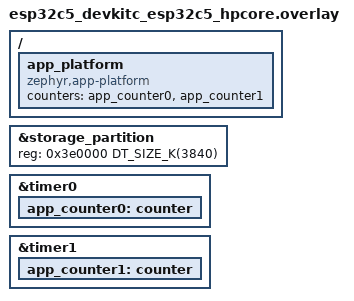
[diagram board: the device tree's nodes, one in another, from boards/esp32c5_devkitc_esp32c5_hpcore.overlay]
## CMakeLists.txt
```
# SPDX-License-Identifier: Apache-2.0

cmake_minimum_required(VERSION 3.20.0)
find_package(Zephyr REQUIRED HINTS $ENV{ZEPHYR_BASE})
project(app_platform_test)

target_sources(app PRIVATE src/main.c src/loader_neg.c src/abi.c src/caps.c src/keys.c
  src/module_run.c)
target_sources_ifdef(CONFIG_USERSPACE app PRIVATE src/hostile.c)
if(CONFIG_APP_PLATFORM_APP_THREADS GREATER 0)
  target_sources(app PRIVATE src/threads.c)
endif()
if(CONFIG_APP_PLATFORM_APP_HEAP_POOL_SIZE GREATER 0)
  target_sources(app PRIVATE src/heap.c)
endif()
target_sources_ifdef(CONFIG_APP_PLATFORM_CPU_AFFINITY app PRIVATE src/smp.c)

set(gen_dir ${ZEPHYR_BINARY_DIR}/include/generated)
set(key_dir ${CMAKE_CURRENT_SOURCE_DIR}/keys)
set(ext_src ${PROJECT_SOURCE_DIR}/module/src/test_mod.c)
set(bin ${PROJECT_BINARY_DIR}/llext/test_mod.llext)

app_platform_add_module(test_ext OUTPUT ${bin} SOURCES ${ext_src})
llext_include_directories(test_ext ${gen_dir})
generate_inc_file_for_target(app ${bin} ${gen_dir}/test_mod.inc)

# A module calling a service the firmware is built without.
set(absent_bin ${PROJECT_BINARY_DIR}/llext/absent_mod.llext)
app_platform_add_module(absent_ext OUTPUT ${absent_bin}
  SOURCES ${PROJECT_SOURCE_DIR}/module/src/absent_mod.c)
generate_inc_file_for_target(app ${absent_bin} ${gen_dir}/absent_mod.inc)

# A module importing a function outside the exported interface.
set(forbidden_bin ${PROJECT_BINARY_DIR}/llext/forbidden_mod.llext)
app_platform_add_module(forbidden_ext OUTPUT ${forbidden_bin}
  SOURCES ${PROJECT_SOURCE_DIR}/module/src/forbidden_mod.c)
generate_inc_file_for_target(app ${forbidden_bin} ${gen_dir}/forbidden_mod.inc)

# test_sign(<tag> <module> <name> [-D<input>=<value>...])
#
# Signs <module> as application <name>, version 1, requesting LOG, with the
# test publisher key 1 of test_keys.yaml, into <tag>.manifest.inc and
# <tag>.sig.inc. The extra arguments override those inputs of
# sign_module.cmake: an empty APP_SIGNING_KEY signs with the key under KEY_DIR,
# by default the development key.
function(test_sign tag module name)
  set(out_mf  ${gen_dir}/${tag}.manifest.inc)
  set(out_sig ${gen_dir}/${tag}.sig.inc)
  string(MAKE_C_IDENTIFIER ${tag} target)

  add_custom_command(
    OUTPUT  ${out_mf} ${out_sig}
    COMMAND ${CMAKE_COMMAND}
      -DMODULE_BIN=${module}
      -DKEY_DIR=${key_dir}
      -DAPP_SIGNING_KEY=${key_dir}/publisher_a.pem
      -DAPP_SIGNING_KEY_ID=1
      -DAPP_NAME=${name}
      -DAPP_VERSION=1
      -DAPP_REQUESTED_CAPS=LOG
      -DABI_FILE=${APP_PLATFORM_ABI_FILE}
      ${ARGN}
      -DOUT_MF_INC=${out_mf}
      -DOUT_SIG_INC=${out_sig}
      -DPYTHON_EXECUTABLE=${PYTHON_EXECUTABLE}
      -P ${ZEPHYR_BASE}/subsys/app_platform/cmake/sign_module.cmake
    DEPENDS ${module} ${APP_PLATFORM_ABI_FILE}
  )
  add_custom_target(${target}_sign DEPENDS ${out_mf} ${out_sig})
  add_dependencies(${target}_sign app_platform_abi)
  add_dependencies(app ${target}_sign)
endfunction()

test_sign(test_mod ${bin} testmod)

# The same module signed for another interface major version, under a manifest
# carrying fields past the ones the firmware knows, under one cut short of
# them, signed for another target, with a heap, and requesting and requiring
# more capabilities.
test_sign(test_mod.badabi ${bin} testmod -DABI_MAJOR_OVERRIDE=0xffff)
test_sign(test_mod.long ${bin} testmod -DMANIFEST_LEN=200)
test_sign(test_mod.short ${bin} testmod -DMANIFEST_LEN=100)
test_sign(test_mod.target ${bin} testmod -DTARGET_OVERRIDE=0)
test_sign(test_mod.heap ${bin} testmod -DAPP_HEAP_SIZE=992)
test_sign(test_mod.caps ${bin} testmod -DAPP_REQUESTED_CAPS=LOG,TIME,RANDOM
  -DAPP_REQUIRED_CAPS=LOG,TIME)

# The module importing a forbidden function, signed without the signer's import
# check for the loader's.
test_sign(forbidden_mod ${forbidden_bin} forbidden -DSKIP_IMPORT_CHECK=1)

# The same module signed with the development key, with a key test_keys.yaml
# does not list, with a revoked key, and with publisher key 2, whose ceiling is
# LOG and whose names start with b_: within its limits, requiring a capability
# outside its ceiling and under a name outside its prefix. The signer refuses
# all but one of them, so its key check is skipped.
test_sign(test_mod.dev ${bin} testmod -DAPP_SIGNING_KEY= -DAPP_SIGNING_KEY_ID=0
  -DSKIP_KEY_CHECK=1)
test_sign(test_mod.unknown ${bin} testmod -DKEY_DIR=${PROJECT_BINARY_DIR}/unlisted_key
  -DAPP_SIGNING_KEY= -DAPP_SIGNING_KEY_ID=7 -DSKIP_KEY_CHECK=1)
test_sign(test_mod.revoked ${bin} testmod -DAPP_SIGNING_KEY=${key_dir}/revoked.pem
  -DAPP_SIGNING_KEY_ID=3 -DSKIP_KEY_CHECK=1)
test_sign(test_mod.b ${bin} b_mod -DAPP_SIGNING_KEY=${key_dir}/publisher_b.pem
  -DAPP_SIGNING_KEY_ID=2 -DAPP_REQUESTED_CAPS=LOG,TIME,RANDOM -DAPP_REQUIRED_CAPS=LOG)
test_sign(test_mod.breq ${bin} b_req -DAPP_SIGNING_KEY=${key_dir}/publisher_b.pem
  -DAPP_SIGNING_KEY_ID=2 -DAPP_REQUESTED_CAPS=LOG,TIME -DAPP_REQUIRED_CAPS=LOG,TIME
  -DSKIP_KEY_CHECK=1)
test_sign(test_mod.bname ${bin} testmod -DAPP_SIGNING_KEY=${key_dir}/publisher_b.pem
  -DAPP_SIGNING_KEY_ID=2 -DSKIP_KEY_CHECK=1)

# A signed-but-malformed module (out-of-section relocation) for the loader's
# relocation bounds-check test.
set(evil    ${gen_dir}/evil_mod.inc)
set(evil_mf ${gen_dir}/evil_mod.manifest.inc)
set(evil_sig ${gen_dir}/evil_mod.sig.inc)

add_custom_command(
  OUTPUT  ${evil} ${evil_mf} ${evil_sig}
  COMMAND ${CMAKE_COMMAND}
    -DMODULE_BIN=${bin}
    -DAPP_SIGNING_KEY=${key_dir}/publisher_a.pem
    -DAPP_SIGNING_KEY_ID=1
    -DAPP_NAME=evil
    -DAPP_VERSION=1
    -DAPP_REQUESTED_CAPS=LOG
    -DABI_FILE=${APP_PLATFORM_ABI_FILE}
    -DOUT_INC=${evil}
    -DOUT_MF_INC=${evil_mf}
    -DOUT_SIG_INC=${evil_sig}
    -DPYTHON_EXECUTABLE=${PYTHON_EXECUTABLE}
    -DZEPHYR_BASE=${ZEPHYR_BASE}
    -P ${CMAKE_CURRENT_SOURCE_DIR}/cmake/make_evil.cmake
  DEPENDS ${bin} ${APP_PLATFORM_ABI_FILE}
)
add_custom_target(test_evil DEPENDS ${evil} ${evil_mf} ${evil_sig})
add_dependencies(test_evil app_platform_abi)
add_dependencies(app test_evil)
```

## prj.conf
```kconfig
CONFIG_ZTEST=y

CONFIG_APPLICATION_DEFINED_SYSCALL=y

CONFIG_APP_PLATFORM=y
CONFIG_APP_PLATFORM_MAX_APPS=4
CONFIG_APP_PLATFORM_APP_THREADS=2
CONFIG_APP_PLATFORM_APP_HEAP_POOL_SIZE=12288
CONFIG_APP_PLATFORM_APP_HEAP_MAX_BYTES=65536
CONFIG_APP_PLATFORM_LOADER=y
CONFIG_APP_PLATFORM_DEV_KEY=y
CONFIG_APP_PLATFORM_KEYS_FILE="test_keys.yaml"
CONFIG_APP_PLATFORM_SERVICES=y
CONFIG_APP_PLATFORM_REGISTRY=y

CONFIG_TASK_WDT=y
CONFIG_TASK_WDT_CHANNELS=6
CONFIG_TASK_WDT_HW_FALLBACK=n

CONFIG_LLEXT=y
CONFIG_LLEXT_HEAP_SIZE=64
CONFIG_LLEXT_TYPE_ELF_RELOCATABLE=y

CONFIG_FLASH=y
CONFIG_FLASH_MAP=y
CONFIG_FILE_SYSTEM=y
CONFIG_FILE_SYSTEM_LITTLEFS=y

CONFIG_PSA_CRYPTO=y
CONFIG_MBEDTLS_ENABLE_HEAP=y
CONFIG_PSA_WANT_ALG_SHA_256=y
CONFIG_PSA_WANT_ALG_ECDSA=y
CONFIG_PSA_WANT_ECC_SECP_R1_256=y
CONFIG_PSA_WANT_KEY_TYPE_ECC_PUBLIC_KEY=y
CONFIG_MBEDTLS_PSA_P256M_DRIVER_ENABLED=y

CONFIG_ENTROPY_GENERATOR=y

CONFIG_LOG=y
CONFIG_LOG_MODE_MINIMAL=y

CONFIG_MAIN_STACK_SIZE=4096
CONFIG_ZTEST_STACK_SIZE=4096
CONFIG_HEAP_MEM_POOL_SIZE=32768

CONFIG_SENSOR=y
CONFIG_APP_PLATFORM_SENSOR=y
CONFIG_APP_PLATFORM_FS=y
CONFIG_GPIO=y
CONFIG_APP_PLATFORM_IO=y
CONFIG_APP_PLATFORM_EVENTS=y
CONFIG_FS_LITTLEFS_NUM_FILES=8
CONFIG_COUNTER=y
CONFIG_APP_PLATFORM_COUNTER=y
```

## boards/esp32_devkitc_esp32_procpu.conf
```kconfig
# The llext instruction heap lives in IRAM here, and its k_heap needs the
# big-only sys_heap variant or heap init faults before the console is up.
CONFIG_SYS_HEAP_BIG_ONLY=y
```

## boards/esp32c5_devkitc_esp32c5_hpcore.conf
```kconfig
# Internal RAM is short in the user mode build, which reserves a privileged
# stack for every application thread.
CONFIG_APP_PLATFORM_APP_HEAP_POOL_SIZE=3072
```

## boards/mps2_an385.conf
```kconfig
# Without an entropy driver mbed TLS runs its own DRBG from its heap.
CONFIG_MBEDTLS_HEAP_SIZE=4096
```

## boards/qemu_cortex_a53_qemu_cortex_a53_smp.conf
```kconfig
# Without an entropy driver mbed TLS runs its own DRBG from its heap.
CONFIG_MBEDTLS_HEAP_SIZE=4096
CONFIG_APP_PLATFORM_CPU_AFFINITY=y
# The CPU affinity suite counts thread switch-ins per CPU.
CONFIG_TRACING=y
CONFIG_TRACING_USER=y
```

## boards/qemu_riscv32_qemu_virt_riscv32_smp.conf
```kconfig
# Without an entropy driver mbed TLS runs its own DRBG from its heap.
CONFIG_MBEDTLS_HEAP_SIZE=4096
# Ticks match milliseconds, so the test module needs no 64-bit division helper.
CONFIG_SYS_CLOCK_TICKS_PER_SEC=1000
CONFIG_APP_PLATFORM_CPU_AFFINITY=y
# The CPU affinity suite counts thread switch-ins per CPU.
CONFIG_TRACING=y
CONFIG_TRACING_USER=y
```

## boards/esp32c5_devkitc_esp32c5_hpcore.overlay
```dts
/*
 * Copyright (c) 2026 Espressif Systems (Shanghai) Co., Ltd.
 *
 * SPDX-License-Identifier: Apache-2.0
 *
 * Enlarge the storage partition for the application store. Under simple boot
 * the second firmware slot is unused, so its region is reassigned to storage,
 * growing the littlefs area from 192 KB to 3.8 MB for many or larger apps. The
 * code partition and the low-power-core slots are left untouched.
 */

/delete-node/ &slot1_partition;

&storage_partition {
	reg = <0x3e0000 DT_SIZE_K(3840)>;
};

/* Two counter instances for the hardware counter service: the suite grants one
 * and withholds the other, so the per-instance grant is testable.
 */
&timer0 {
	status = "okay";

	app_counter0: counter {
		status = "okay";
	};
};

&timer1 {
	status = "okay";

	app_counter1: counter {
		status = "okay";
	};
};

/ {
	app_platform {
		compatible = "zephyr,app-platform";
		counters = <&app_counter0 &app_counter1>;
	};
};
```

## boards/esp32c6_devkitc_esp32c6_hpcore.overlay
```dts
/*
 * Copyright (c) 2026 Espressif Systems (Shanghai) Co., Ltd.
 *
 * SPDX-License-Identifier: Apache-2.0
 *
 * Enlarge the storage partition for the application store. Under simple boot
 * the second firmware slot is unused, so its region is reassigned to storage.
 * The code partition and the low-power-core slots are left untouched.
 */

/delete-node/ &slot1_partition;

&storage_partition {
	reg = <0x1e0000 DT_SIZE_K(1792)>;
};

/* Two counter instances for the hardware counter service: the suite grants one
 * and withholds the other, so the per-instance grant is testable.
 */
&timer0 {
	status = "okay";

	app_counter0: counter {
		status = "okay";
	};
};

&timer1 {
	status = "okay";

	app_counter1: counter {
		status = "okay";
	};
};

/ {
	app_platform {
		compatible = "zephyr,app-platform";
		counters = <&app_counter0 &app_counter1>;
	};
};
```

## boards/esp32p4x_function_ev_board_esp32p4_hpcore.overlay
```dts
/*
 * Copyright (c) 2026 Espressif Systems (Shanghai) Co., Ltd.
 *
 * SPDX-License-Identifier: Apache-2.0
 *
 * Enlarge the storage partition for the application store. Under simple boot
 * the second firmware slot is unused, so its region is reassigned to storage,
 * growing the littlefs area from 192 KB to 3.8 MB for many or larger apps. The
 * code partition and the low-power-core slots are left untouched.
 */

/delete-node/ &slot1_partition;

&storage_partition {
	reg = <0x7e0000 DT_SIZE_K(3840)>;
};

/* Two counter instances for the hardware counter service: the suite grants one
 * and withholds the other, so the per-instance grant is testable.
 */
&timer0 {
	status = "okay";

	app_counter0: counter {
		status = "okay";
	};
};

&timer1 {
	status = "okay";

	app_counter1: counter {
		status = "okay";
	};
};

/ {
	app_platform {
		compatible = "zephyr,app-platform";
		counters = <&app_counter0 &app_counter1>;
	};
};
```

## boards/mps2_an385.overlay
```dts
/*
 * Copyright (c) 2026 Espressif Systems (Shanghai) Co., Ltd.
 *
 * SPDX-License-Identifier: Apache-2.0
 */

/ {
	app_platform {
		compatible = "zephyr,app-platform";
		counters = <&timer0 &timer1>;
	};
};
```

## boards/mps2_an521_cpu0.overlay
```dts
/*
 * Copyright (c) 2026 Espressif Systems (Shanghai) Co., Ltd.
 *
 * SPDX-License-Identifier: Apache-2.0
 */

#include <mem.h>
#include "sim_flash.dtsi"

/ {
	app_platform {
		compatible = "zephyr,app-platform";
		counters = <&timer0 &timer1>;
	};
};
```

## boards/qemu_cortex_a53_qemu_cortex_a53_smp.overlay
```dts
/*
 * Copyright (c) 2026 Espressif Systems (Shanghai) Co., Ltd.
 *
 * SPDX-License-Identifier: Apache-2.0
 */

#include <mem.h>
#include "sim_flash.dtsi"
```

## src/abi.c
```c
/*
 * Copyright (c) 2026 Espressif Systems (Shanghai) Co., Ltd.
 *
 * SPDX-License-Identifier: Apache-2.0
 */

/* The functions the firmware exports to loadable modules. */

#include <zephyr/ztest.h>
#include <zephyr/app_platform/app_loader.h>
#include <zephyr/app_platform/app_manifest.h>
#include <zephyr/app_platform/app_platform.h>
#include <zephyr/llext/buf_loader.h>
#include <zephyr/llext/llext.h>
#include <zephyr/kernel.h>
#include <errno.h>
#include <string.h>

#include "module_run.h"

/* Argument that makes the test module check the kernel services and return. */
#define TIME_PROBE ((void *)0x5449U)

/* Argument that makes the test module check 64-bit division and return. */
#define DIV_PROBE ((void *)0x4449U)

static const uint8_t mod_bytes[] = {
#include "test_mod.inc"
};
static const uint8_t mod_manifest[] = {
#include "test_mod.manifest.inc"
};
static const uint8_t mod_sig[] = {
#include "test_mod.sig.inc"
};
static const uint8_t absent_bytes[] __aligned(8) = {
#include "absent_mod.inc"
};

ZTEST(module_abi, test_kernel_services)
{
	struct app_manifest mf;
	struct llext *ext = NULL;
	void *entry = NULL;
	int id;

	zassert_true(sizeof(mod_bytes) <= sizeof(module_work), "module too big");
	memcpy(module_work, mod_bytes, sizeof(mod_bytes));
	memcpy(&mf, mod_manifest, sizeof(mf));
	zassert_equal(app_loader_verify_load_manifest(&mf, sizeof(mf), mod_sig, sizeof(mod_sig),
						      module_work, sizeof(mod_bytes), "app_main",
						      &ext, &entry),
		      0);

	module_watch(mf.name);
	id = app_platform_launch_llext(mf.name, ext, (app_entry_t)entry, TIME_PROBE,
				       APP_CAP_LOG);
	zassert_true(id >= 0, "launch rc %d", id);
	zassert_equal(module_wait_end(id, 3000), 0, "the module did not return");
}

ZTEST(module_abi, test_64bit_division)
{
	struct app_manifest mf;
	struct llext *ext = NULL;
	void *entry = NULL;
	int id;

	memcpy(module_work, mod_bytes, sizeof(mod_bytes));
	memcpy(&mf, mod_manifest, sizeof(mf));
	zassert_equal(app_loader_verify_load_manifest(&mf, sizeof(mf), mod_sig, sizeof(mod_sig),
						      module_work, sizeof(mod_bytes), "app_main",
						      &ext, &entry),
		      0);

	module_watch(mf.name);
	id = app_platform_launch_llext(mf.name, ext, (app_entry_t)entry, DIV_PROBE, APP_CAP_LOG);
	zassert_true(id >= 0, "launch rc %d", id);
	zassert_equal(module_wait_end(id, 3000), 0, "the module did not return");
}

ZTEST(module_abi, test_missing_service_fails_to_link)
{
	struct llext_buf_loader buf_loader =
		LLEXT_TEMPORARY_BUF_LOADER(absent_bytes, sizeof(absent_bytes));
	struct llext_load_param ldr_parm = LLEXT_LOAD_PARAM_DEFAULT;
	struct llext *ext = NULL;
	int ret;

	/* A missing symbol reached through the PLT reports -ENOENT. */
	ret = llext_load(&buf_loader.loader, "absent", &ext, &ldr_parm);
	zassert_true(ret == -ENODATA || ret == -ENOENT, "load rc %d", ret);
	zassert_is_null(ext);
}

ZTEST_SUITE(module_abi, NULL, NULL, NULL, NULL, NULL);
```

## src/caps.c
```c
/*
 * Copyright (c) 2026 Espressif Systems (Shanghai) Co., Ltd.
 *
 * SPDX-License-Identifier: Apache-2.0
 */

/* The capabilities a loaded module holds: what its signed manifest requests,
 * bounded by the launcher, or what the launcher allows without a manifest.
 */

#include <zephyr/ztest.h>
#include <zephyr/app_platform/app_caps.h>
#include <zephyr/app_platform/app_loader.h>
#include <zephyr/app_platform/app_manifest.h>
#include <zephyr/app_platform/app_platform.h>
#include <zephyr/app_platform/app_registry.h>
#include <zephyr/llext/llext.h>
#include <zephyr/kernel.h>
#include <errno.h>
#include <string.h>

#include "module_run.h"

static const uint8_t mod_bytes[] = {
#include "test_mod.inc"
};
static const uint8_t caps_manifest[] = {
#include "test_mod.caps.manifest.inc"
};
static const uint8_t caps_sig[] = {
#include "test_mod.caps.sig.inc"
};

#define REQUESTED (APP_CAP_LOG | APP_CAP_TIME | APP_CAP_RANDOM)

static struct llext *load_caps_module(struct app_manifest *mf, void **entry)
{
	struct llext *ext = NULL;

	zassert_true(sizeof(mod_bytes) <= sizeof(module_work), "module too big");
	memcpy(module_work, mod_bytes, sizeof(mod_bytes));
	memcpy(mf, caps_manifest, sizeof(*mf));
	zassert_equal(app_loader_verify_load_manifest(mf, sizeof(*mf), caps_sig, sizeof(caps_sig),
						      module_work, sizeof(mod_bytes), "app_main",
						      &ext, entry),
		      0);
	return ext;
}

static void unload(struct llext *ext)
{
	app_loader_forget(ext);
	llext_unload(&ext);
}

/* Launch stopped, read the capabilities the application holds, remove it. */
static int held_caps(const char *name, struct llext *ext, void *entry, app_caps_t ceiling,
		     app_caps_t *caps)
{
	const struct app_launch_opts opts = {.stopped = true};
	struct app_platform_status st;
	int id = app_platform_launch_llext_opts(name, ext, (app_entry_t)entry, NULL, ceiling,
						&opts);

	if (id < 0) {
		return id;
	}
	zassert_equal(app_platform_status(id, &st), 0);
	*caps = st.caps;
	zassert_equal(app_platform_remove(id), 0);
	for (int i = 0; i < 400 && app_platform_status(id, &st) == 0; i++) {
		k_msleep(5);
	}
	return 0;
}

ZTEST(module_caps, test_manifest_request_bounds_the_ceiling)
{
	struct app_manifest mf;
	app_caps_t caps = 0U;
	void *entry = NULL;
	struct llext *ext = load_caps_module(&mf, &entry);

	zassert_equal(mf.requested_caps, REQUESTED);
	zassert_equal(held_caps(mf.name, ext, entry, APP_CAP_ALL, &caps), 0);
	zassert_equal(caps, REQUESTED, "held %#llx", (unsigned long long)caps);
}

ZTEST(module_caps, test_optional_caps_outside_ceiling_dropped)
{
	struct app_manifest mf;
	app_caps_t caps = 0U;
	void *entry = NULL;
	struct llext *ext = load_caps_module(&mf, &entry);

	zassert_equal(held_caps(mf.name, ext, entry, APP_CAP_LOG | APP_CAP_TIME | APP_CAP_GPIO,
				&caps),
		      0);
	zassert_equal(caps, APP_CAP_LOG | APP_CAP_TIME, "held %#llx", (unsigned long long)caps);
}

ZTEST(module_caps, test_required_caps_outside_ceiling_refused)
{
	struct app_manifest mf;
	app_caps_t caps = 0U;
	void *entry = NULL;
	struct llext *ext = load_caps_module(&mf, &entry);

	zassert_equal(held_caps(mf.name, ext, entry, APP_CAP_LOG | APP_CAP_RANDOM, &caps), -EPERM);
	for (int i = 0; i < app_platform_count(); i++) {
		struct app_platform_status st;

		zassert_false(app_platform_status(i, &st) == 0 && st.name != NULL &&
				      strcmp(st.name, mf.name) == 0,
			      "a refused launch kept a slot");
	}
	unload(ext);
}

ZTEST(module_caps, test_module_without_manifest_holds_ceiling)
{
	struct app_manifest mf;
	struct llext *ext = NULL;
	app_caps_t requested;
	app_caps_t required;
	app_caps_t key_caps;
	app_caps_t caps = 0U;
	uint32_t key_id;
	void *entry = NULL;

	memcpy(&mf, caps_manifest, sizeof(mf));
	memcpy(module_work, mod_bytes, sizeof(mod_bytes));
	zassert_equal(app_loader_verify_load("hashed", module_work, sizeof(mod_bytes),
					     mf.module_sha256, "app_main", &ext, &entry),
		      0);
	zassert_equal(app_loader_manifest_caps(ext, &requested, &required), -ENOENT);
	zassert_equal(app_loader_key(ext, &key_id, &key_caps), -ENOENT);
	zassert_equal(held_caps("hashed", ext, entry, APP_CAP_LOG | APP_CAP_GPIO, &caps), 0);
	zassert_equal(caps, APP_CAP_LOG | APP_CAP_GPIO, "held %#llx", (unsigned long long)caps);
}

static int autostart_with_small_ceiling(const struct app_record *rec, void *user)
{
	struct app_manifest mf;
	void *entry = NULL;
	struct llext *ext;
	int rc;

	ARG_UNUSED(user);
	if (strcmp(rec->name, "testmod") != 0) {
		return -ENOENT;
	}
	ext = load_caps_module(&mf, &entry);
	rc = app_platform_launch_llext(mf.name, ext, (app_entry_t)entry, NULL, APP_CAP_LOG);
	if (rc < 0) {
		unload(ext);
	}
	return rc;
}

ZTEST(module_caps, test_refused_autostart_is_recorded)
{
	int err = 1;

	zassert_equal(app_registry_load(), 0);
	zassert_equal(app_registry_install("testmod", true), 0);
	zassert_equal(app_registry_autostart_result("testmod", &err), 0);
	zassert_equal(err, 0);
	zassert_true(app_registry_autostart_all(autostart_with_small_ceiling, NULL) >= 0);
	zassert_equal(app_registry_autostart_result("testmod", &err), 0);
	zassert_equal(err, -EPERM, "recorded %d", err);

	zassert_equal(app_registry_install("testmod", true), 0);
	zassert_equal(app_registry_autostart_result("testmod", &err), 0);
	zassert_equal(err, 0, "a reinstall kept the refusal");
	zassert_equal(app_registry_uninstall("testmod"), 0);
	zassert_equal(app_registry_autostart_result("testmod", &err), -ENOENT);
}

ZTEST_SUITE(module_caps, NULL, NULL, NULL, NULL, NULL);
```

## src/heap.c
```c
/*
 * Copyright (c) 2026 Espressif Systems (Shanghai) Co., Ltd.
 *
 * SPDX-License-Identifier: Apache-2.0
 */

/* Per-application heap. */

#include <zephyr/ztest.h>
#include <zephyr/app_platform/app_platform.h>
#include <zephyr/app_platform/app_services.h>
#include <zephyr/app_platform/app_caps.h>
#include <zephyr/app_platform/app_heap.h>
#include <zephyr/app_platform/app_loader.h>
#include <zephyr/app_platform/app_manifest.h>
#include <zephyr/app_memory/app_memdomain.h>
#include <zephyr/sys/libc-hooks.h>
#include <zephyr/kernel.h>
#include <string.h>
#include <errno.h>

#include "module_run.h"

#define HEAP_SZ  992U
#define POOL_SZ  CONFIG_APP_PLATFORM_APP_HEAP_POOL_SIZE
#define HEAP_MAX CONFIG_APP_PLATFORM_APP_HEAP_MAX_BYTES
#define PATTERN  0xa5c3e1f7U
#define ROUNDS   200
#define THR_CAPS (APP_CAP_LOG | APP_CAP_THREAD)

/* Argument that makes the test module exercise its heap and return. */
#define HEAP_PROBE ((void *)0x4850U)

static const uint8_t mod_bytes[] = {
#include "test_mod.inc"
};
static const uint8_t mod_manifest[] = {
#include "test_mod.heap.manifest.inc"
};
static const uint8_t mod_sig[] = {
#include "test_mod.heap.sig.inc"
};

K_APPMEM_PARTITION_DEFINE(heap_part);

struct heap_report {
	int rc[4];
	uintptr_t base;
	size_t size;
	uint32_t found;
	int mode;
	bool done;
};

K_APP_BMEM(heap_part) static struct heap_report rep;

/* Heap size of the last launch, read before the application started. */
static size_t launched_heap;

#ifdef CONFIG_USERSPACE
/* Domains the report partition was added to. */
static struct k_mem_domain *doms[CONFIG_APP_PLATFORM_MAX_APPS];

static bool has_heap_part(struct k_mem_domain *dom)
{
	for (int i = 0; i < CONFIG_MAX_DOMAIN_PARTITIONS; i++) {
		if (dom->partitions[i].start == heap_part.start &&
		    dom->partitions[i].size == heap_part.size) {
			return true;
		}
	}
	return false;
}
#endif

static int slot_of(const char *name)
{
	for (int i = 0; i < app_platform_count(); i++) {
		struct app_platform_status st;

		if (app_platform_status(i, &st) == 0 && st.name != NULL &&
		    strcmp(st.name, name) == 0) {
			return i;
		}
	}
	return -1;
}

static bool wait_slot_free(const char *name, int ms)
{
	for (int i = 0; i < ms / 5; i++) {
		if (slot_of(name) < 0) {
			k_msleep(10);
			return true;
		}
		k_msleep(5);
	}
	return slot_of(name) < 0;
}

static bool wait_done(int ms)
{
	for (int i = 0; i < ms / 5 && !rep.done; i++) {
		k_msleep(5);
	}
	return rep.done;
}

static size_t heap_bytes(int id)
{
	struct app_platform_status st;

	zassert_equal(app_platform_status(id, &st), 0);
	return st.heap_bytes;
}

static int launch(const char *name, app_entry_t entry, app_caps_t caps, size_t heap_size)
{
	const struct app_def def = {
		.name = name,
		.source = APP_BUILTIN,
		.entry = entry,
		.caps = caps,
		.heap_size = heap_size,
		.stopped = true,
	};
	int id = app_platform_launch(&def);

#ifdef CONFIG_USERSPACE
	if (id >= 0) {
		struct k_mem_domain *dom = app_platform_domain(id);

		if (!has_heap_part(dom)) {
			zassert_equal(k_mem_domain_add_partition(dom, &heap_part), 0);
		}
		doms[id] = dom;
	}
#endif
	if (id >= 0) {
		launched_heap = heap_bytes(id);
		zassert_equal(app_platform_start(id), id, "%s did not start", name);
	}
	return id;
}

static bool in_region(const void *p, size_t len, uintptr_t base, size_t size)
{
	return (uintptr_t)p >= base && (uintptr_t)p + len <= base + size;
}

static void basic_app(void *arg)
{
	uintptr_t base = 0U;
	size_t size = 0U;
	uint8_t *p;
	uint8_t *q;
	uint8_t *a;
	uint32_t *z;

	ARG_UNUSED(arg);
	rep.rc[0] = app_svc_heap_info(&base, &size);
	rep.base = base;
	rep.size = size;

	p = app_malloc(100);
	if (p == NULL || !in_region(p, 100, base, size)) {
		rep.rc[1] = 1;
		goto out;
	}
	(void)memset(p, 0x5a, 100);
	q = app_realloc(p, 300);
	if (q == NULL || !in_region(q, 300, base, size)) {
		rep.rc[1] = 2;
		goto out;
	}
	for (int i = 0; i < 100; i++) {
		if (q[i] != 0x5aU) {
			rep.rc[1] = 3;
			goto out;
		}
	}
	a = app_aligned_alloc(64, 40);
	if (a == NULL || ((uintptr_t)a % 64U) != 0U || !in_region(a, 40, base, size)) {
		rep.rc[1] = 4;
		goto out;
	}
	app_free(q);
	app_free(a);
	app_free(NULL);

	p = app_malloc(64);
	if (p == NULL) {
		rep.rc[1] = 5;
		goto out;
	}
	(void)memset(p, 0xff, 64);
	app_free(p);
	z = app_calloc(16, sizeof(uint32_t));
	if (z == NULL) {
		rep.rc[1] = 6;
		goto out;
	}
	for (int i = 0; i < 16; i++) {
		if (z[i] != 0U) {
			rep.rc[1] = 7;
			goto out;
		}
	}
	app_free(z);
	if (app_calloc(SIZE_MAX / 2U, 4U) != NULL) {
		rep.rc[1] = 8;
	}
out:
	rep.done = true;
}

ZTEST(memheap, test_alloc_free_calloc_realloc_aligned)
{
	int id = launch("hbasic", basic_app, APP_CAP_LOG, HEAP_SZ);
	size_t bytes;

	zassert_true(id >= 0, "launch rc %d", id);
	bytes = launched_heap;
	zassert_true(bytes >= HEAP_SZ + sizeof(struct app_heap_region), "heap of %zu bytes", bytes);
	zassert_true(wait_slot_free("hbasic", 3000), "hbasic never ended");
	zassert_equal(rep.rc[0], 0, "heap info rc %d", rep.rc[0]);
	zassert_equal(rep.size, bytes, "region %zu, status %zu", rep.size, bytes);
	zassert_equal(rep.rc[1], 0, "allocator check %d failed", rep.rc[1]);
}

static void exhaust_app(void *arg)
{
	void *head = NULL;
	int n = 0;

	ARG_UNUSED(arg);
	for (;;) {
		void **b = app_malloc(32);

		if (b == NULL) {
			break;
		}
		*b = head;
		head = b;
		n++;
	}
	rep.rc[0] = n;
	while (head != NULL) {
		void *next = *(void **)head;

		app_free(head);
		head = next;
	}
	rep.rc[1] = (app_malloc(HEAP_SZ / 2U) != NULL) ? 0 : -ENOMEM;
	rep.done = true;
}

ZTEST(memheap, test_exhaustion_returns_null)
{
	int id = launch("hfull", exhaust_app, APP_CAP_LOG, HEAP_SZ);
	size_t bytes;

	zassert_true(id >= 0, "launch rc %d", id);
	bytes = launched_heap;
	zassert_true(wait_slot_free("hfull", 3000), "hfull never ended");
	zassert_true(rep.rc[0] > 0, "no allocation succeeded");
	zassert_true((size_t)rep.rc[0] * 32U <= bytes, "%d blocks from %zu bytes", rep.rc[0],
		     bytes);
	zassert_equal(rep.rc[1], 0, "freed heap did not coalesce");
}

static void dirty_app(void *arg)
{
	uintptr_t base = 0U;
	size_t size = 0U;

	ARG_UNUSED(arg);
	if (app_svc_heap_info(&base, &size) != 0) {
		rep.rc[0] = -ENOENT;
	} else if (rep.mode == 0) {
		uint32_t *p = app_malloc(HEAP_SZ / 2U);

		for (size_t i = 0U; p != NULL && i < HEAP_SZ / 2U / sizeof(uint32_t); i++) {
			p[i] = PATTERN;
		}
		rep.rc[0] = (p != NULL) ? 0 : -ENOMEM;
	} else {
		const uint32_t *w = (const uint32_t *)base;

		rep.found = 0U;
		for (size_t i = 0U; i < size / sizeof(uint32_t); i++) {
			if (w[i] == PATTERN) {
				rep.found++;
			}
		}
		rep.rc[0] = 0;
	}
	rep.done = true;
	for (;;) {
		k_msleep(10);
	}
}

static void dirty_step(int id, int mode)
{
	rep.mode = mode;
	rep.done = false;
	rep.found = UINT32_MAX;
	zassert_equal(app_platform_stop(id), 0);
	k_msleep(20);
	zassert_true(app_platform_start(id) >= 0);
	zassert_true(wait_done(2000), "application did not run");
	zassert_equal(rep.rc[0], 0, "rc %d", rep.rc[0]);
}

ZTEST(memheap, test_region_zeroed_for_restart_and_next_app)
{
	int id = launch("hdirty", dirty_app, APP_CAP_LOG, HEAP_SZ);
	int id2;

	zassert_true(id >= 0, "launch rc %d", id);
	zassert_true(wait_done(2000));
	zassert_equal(rep.rc[0], 0, "fill rc %d", rep.rc[0]);

	dirty_step(id, 1);
	zassert_equal(rep.found, 0U, "a restart kept %u words", rep.found);

	dirty_step(id, 0);
	zassert_equal(app_platform_remove(id), 0);
	zassert_true(wait_slot_free("hdirty", 3000));

	rep.mode = 1;
	rep.done = false;
	rep.found = UINT32_MAX;
	id2 = launch("hscan", dirty_app, APP_CAP_LOG, HEAP_SZ);
	zassert_equal(id2, id, "not the same slot (%d, %d)", id2, id);
	zassert_true(wait_done(2000));
	zassert_equal(rep.found, 0U, "the next application saw %u words", rep.found);
	zassert_equal(app_platform_remove(id2), 0);
	zassert_true(wait_slot_free("hscan", 3000));
}

static void quit_app(void *arg)
{
	ARG_UNUSED(arg);
}

ZTEST(memheap, test_launches_do_not_leak_the_pool)
{
	for (int round = 0; round < 24; round++) {
		int id = launch("hleak", quit_app, APP_CAP_LOG, HEAP_SZ);

		zassert_true(id >= 0, "round %d launch rc %d", round, id);
		zassert_true(wait_slot_free("hleak", 3000), "round %d not reclaimed", round);
	}
}

ZTEST(memheap, test_heap_above_limits_refused)
{
	int id = launch("hbig", quit_app, APP_CAP_LOG, HEAP_MAX + 1U);

	zassert_equal(id, -E2BIG, "rc %d", id);
	zassert_true(slot_of("hbig") < 0, "a refused launch kept its slot");

	if (POOL_SZ <= HEAP_MAX) {
		id = launch("hbig", quit_app, APP_CAP_LOG, POOL_SZ);
		zassert_equal(id, -ENOMEM, "rc %d", id);
		zassert_true(slot_of("hbig") < 0, "a refused launch kept its slot");
	}

	id = launch("hbig", quit_app, APP_CAP_LOG, HEAP_SZ);
	zassert_true(id >= 0, "launch after refusals rc %d", id);
	zassert_true(wait_slot_free("hbig", 3000));
}

static void no_heap_app(void *arg)
{
	uintptr_t base;
	size_t size;

	ARG_UNUSED(arg);
	rep.rc[0] = app_svc_heap_info(&base, &size);
	rep.rc[1] = (app_malloc(8) == NULL) ? 0 : 1;
	rep.done = true;
}

ZTEST(memheap, test_no_heap_declared)
{
	uintptr_t base;
	size_t size;
	int id = launch("hnone", no_heap_app, APP_CAP_LOG, 0U);

	zassert_true(id >= 0, "launch rc %d", id);
	zassert_equal(launched_heap, 0U);
	zassert_true(wait_slot_free("hnone", 3000));
	zassert_equal(rep.rc[0], -ENOENT, "heap info rc %d", rep.rc[0]);
	zassert_equal(rep.rc[1], 0, "allocated without a heap");
	zassert_equal(app_svc_heap_info(&base, &size), -EPERM);
}

static int churn(int tag)
{
	int bad = 0;

	for (int i = 0; i < ROUNDS; i++) {
		size_t len = 8U + (size_t)((i * 7 + tag * 13) % 57);
		uint8_t *p = app_malloc(len);

		if (p == NULL) {
			bad++;
			continue;
		}
		(void)memset(p, tag, len);
		k_yield();
		for (size_t j = 0U; j < len; j++) {
			if (p[j] != (uint8_t)tag) {
				bad++;
				break;
			}
		}
		app_free(p);
	}
	return bad;
}

static void churn_worker(void *arg)
{
	int tag = (int)(uintptr_t)arg;

	rep.rc[tag] = churn(tag);
}

static void churn_app(void *arg)
{
	int h1 = app_svc_thread_spawn(churn_worker, (void *)1, 0);
	int h2 = app_svc_thread_spawn(churn_worker, (void *)2, 1);

	ARG_UNUSED(arg);
	rep.rc[3] = churn(3);
	rep.rc[0] = (h1 > 0 && h2 > 0) ? 0 : -EAGAIN;
	if (h1 > 0) {
		(void)app_svc_thread_join(h1, -1);
	}
	if (h2 > 0) {
		(void)app_svc_thread_join(h2, -1);
	}
	rep.done = true;
}

ZTEST(memheap, test_threads_share_the_heap)
{
	if (CONFIG_APP_PLATFORM_APP_THREADS < 2) {
		ztest_test_skip();
	}
	for (int i = 1; i < 4; i++) {
		rep.rc[i] = -1;
	}
	zassert_true(launch("hthr", churn_app, THR_CAPS, HEAP_SZ) >= 0);
	zassert_true(wait_slot_free("hthr", 5000), "hthr never ended");
	zassert_true(rep.done);
	zassert_equal(rep.rc[0], 0, "spawn failed");
	for (int i = 1; i < 4; i++) {
		zassert_equal(rep.rc[i], 0, "thread %d saw %d bad blocks", i, rep.rc[i]);
	}
}

ZTEST(memheap, test_loaded_module_gets_its_signed_heap)
{
	struct app_manifest mf;
	struct llext *ext = NULL;
	void *entry = NULL;
	uint8_t *buf = k_malloc(sizeof(mod_bytes));
	const struct app_launch_opts opts = { .stopped = true };
	size_t bytes;
	int id;

	zassert_not_null(buf);
	memcpy(buf, mod_bytes, sizeof(mod_bytes));
	memcpy(&mf, mod_manifest, sizeof(mf));
	zassert_true(mf.heap_size > 0U, "the test module declares no heap");

	zassert_equal(app_loader_verify_load_manifest(&mf, sizeof(mf), mod_sig, sizeof(mod_sig),
						      buf, sizeof(mod_bytes), "app_main", &ext,
						      &entry),
		      0);
	zassert_equal(app_loader_heap_size(ext), mf.heap_size);

#ifdef CONFIG_USERSPACE
	int need = 1;

	for (int i = 0; i < LLEXT_MEM_PARTITIONS; i++) {
		need += (ext->mem_parts[i].size != 0U) ? 1 : 0;
	}
#ifdef Z_LIBC_PARTITION_EXISTS
	need++;
#endif
	if (need > arch_mem_domain_max_partitions_get()) {
		app_loader_forget(ext);
		llext_unload(&ext);
		k_free(buf);
		ztest_test_skip();
	}
#endif

	module_watch(mf.name);
	id = app_platform_launch_llext_opts(mf.name, ext, (app_entry_t)entry, HEAP_PROBE,
					    APP_CAP_LOG, &opts);
	zassert_true(id >= 0, "launch rc %d", id);
	bytes = heap_bytes(id);
	zassert_equal(app_platform_start(id), id, "%s did not start", mf.name);
	zassert_true(bytes >= mf.heap_size, "heap of %zu bytes", bytes);
	zassert_equal(module_wait_end(id, 3000), 0, "the module's heap probe failed");
	k_free(buf);
}

static void heap_before(void *f)
{
	ARG_UNUSED(f);
	memset(&rep, 0, sizeof(rep));
}

/* Leave the slots' domains with the partitions the other suites expect. */
static void heap_after(void *f)
{
	ARG_UNUSED(f);
#ifdef CONFIG_USERSPACE
	for (int i = 0; i < CONFIG_APP_PLATFORM_MAX_APPS; i++) {
		if (doms[i] != NULL && has_heap_part(doms[i])) {
			(void)k_mem_domain_remove_partition(doms[i], &heap_part);
		}
		doms[i] = NULL;
	}
#endif
}

ZTEST_SUITE(memheap, NULL, NULL, heap_before, heap_after, NULL);
```

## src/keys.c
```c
/*
 * Copyright (c) 2026 Espressif Systems (Shanghai) Co., Ltd.
 *
 * SPDX-License-Identifier: Apache-2.0
 */

/* The trusted key table of test_keys.yaml: key 1 holds every capability, key 2
 * holds LOG and signs only names starting with b_, key 3 is revoked, and the
 * development key is accepted only with CONFIG_APP_PLATFORM_DEV_KEY.
 */

#include <zephyr/ztest.h>
#include <zephyr/app_platform/app_caps.h>
#include <zephyr/app_platform/app_loader.h>
#include <zephyr/app_platform/app_manifest.h>
#include <zephyr/app_platform/app_platform.h>
#include <zephyr/app_platform/app_registry.h>
#include <zephyr/llext/llext.h>
#include <zephyr/fs/fs.h>
#include <zephyr/kernel.h>
#include <errno.h>
#include <string.h>

#include "module_run.h"

static const uint8_t mod_bytes[] = {
#include "test_mod.inc"
};
static const uint8_t a_manifest[] = {
#include "test_mod.manifest.inc"
};
static const uint8_t a_sig[] = {
#include "test_mod.sig.inc"
};
static const uint8_t a_caps_manifest[] = {
#include "test_mod.caps.manifest.inc"
};
static const uint8_t a_caps_sig[] = {
#include "test_mod.caps.sig.inc"
};
static const uint8_t dev_manifest[] = {
#include "test_mod.dev.manifest.inc"
};
static const uint8_t dev_sig[] = {
#include "test_mod.dev.sig.inc"
};
static const uint8_t unknown_manifest[] = {
#include "test_mod.unknown.manifest.inc"
};
static const uint8_t unknown_sig[] = {
#include "test_mod.unknown.sig.inc"
};
static const uint8_t revoked_manifest[] = {
#include "test_mod.revoked.manifest.inc"
};
static const uint8_t revoked_sig[] = {
#include "test_mod.revoked.sig.inc"
};
static const uint8_t b_manifest[] = {
#include "test_mod.b.manifest.inc"
};
static const uint8_t b_sig[] = {
#include "test_mod.b.sig.inc"
};
static const uint8_t breq_manifest[] = {
#include "test_mod.breq.manifest.inc"
};
static const uint8_t breq_sig[] = {
#include "test_mod.breq.sig.inc"
};
static const uint8_t bname_manifest[] = {
#include "test_mod.bname.manifest.inc"
};
static const uint8_t bname_sig[] = {
#include "test_mod.bname.sig.inc"
};

#define REQUESTED (APP_CAP_LOG | APP_CAP_TIME | APP_CAP_RANDOM)

static int load(const uint8_t *mf_bytes, const uint8_t *sig, struct app_manifest *mf,
		struct llext **ext, void **entry)
{
	zassert_true(sizeof(mod_bytes) <= sizeof(module_work), "module too big");
	memcpy(module_work, mod_bytes, sizeof(mod_bytes));
	memcpy(mf, mf_bytes, sizeof(*mf));
	*ext = NULL;
	return app_loader_verify_load_manifest(mf, sizeof(*mf), sig, APP_MANIFEST_SIG_LEN,
					       module_work, sizeof(mod_bytes), "app_main", ext,
					       entry);
}

static int load_file(const char *name, const uint8_t *mf_bytes, const uint8_t *sig,
		     struct app_manifest *mf, struct llext **ext, void **entry)
{
	char path[64];
	int rc;

	memcpy(mf, mf_bytes, sizeof(*mf));
	zassert_equal(app_registry_store_blob(name, mod_bytes, sizeof(mod_bytes)), 0);
	zassert_equal(app_registry_blob_path(name, path, sizeof(path)), 0);
	*ext = NULL;
	rc = app_loader_verify_load_manifest_file(mf, sizeof(*mf), sig, APP_MANIFEST_SIG_LEN, path,
						  "app_main", ext, entry);
	(void)fs_unlink(path);
	return rc;
}

static void unload(struct llext *ext)
{
	app_loader_forget(ext);
	llext_unload(&ext);
}

/* Launch stopped under a launcher ceiling of every capability. */
static int launch_stopped(const char *name, struct llext *ext, void *entry, app_caps_t *caps)
{
	const struct app_launch_opts opts = {.stopped = true};
	struct app_platform_status st;
	int id = app_platform_launch_llext_opts(name, ext, (app_entry_t)entry, NULL, APP_CAP_ALL,
						&opts);

	if (id >= 0) {
		zassert_equal(app_platform_status(id, &st), 0);
		*caps = st.caps;
	}
	return id;
}

static void remove_app(int id)
{
	struct app_platform_status st;

	zassert_equal(app_platform_remove(id), 0);
	for (int i = 0; i < 400 && app_platform_status(id, &st) == 0; i++) {
		k_msleep(5);
	}
}

ZTEST(module_keys, test_listed_key_is_recorded)
{
	struct app_manifest mf;
	struct llext *ext;
	void *entry = NULL;
	app_caps_t key_caps = 0U;
	uint32_t key_id = 0U;

	zassert_equal(load(a_manifest, a_sig, &mf, &ext, &entry), 0);
	zassert_equal(mf.key_id, 1U);
	zassert_equal(app_loader_key(ext, &key_id, &key_caps), 0);
	zassert_equal(key_id, 1U);
	zassert_equal(key_caps, APP_CAP_ALL);
	unload(ext);
}

ZTEST(module_keys, test_development_key)
{
	struct app_manifest mf;
	struct llext *ext;
	void *entry = NULL;
	app_caps_t key_caps = 0U;
	uint32_t key_id = 1U;
	int rc = load(dev_manifest, dev_sig, &mf, &ext, &entry);

	zassert_equal(mf.key_id, 0U);
	if (!IS_ENABLED(CONFIG_APP_PLATFORM_DEV_KEY)) {
		zassert_equal(rc, -ENXIO, "the development key was accepted (%d)", rc);
		zassert_is_null(ext);
		return;
	}
	zassert_equal(rc, 0);
	zassert_equal(app_loader_key(ext, &key_id, &key_caps), 0);
	zassert_equal(key_id, 0U);
	zassert_equal(key_caps, APP_CAP_ALL);
	unload(ext);
}

ZTEST(module_keys, test_unknown_key_refused)
{
	struct app_manifest mf;
	struct llext *ext;
	void *entry = NULL;

	zassert_equal(load(unknown_manifest, unknown_sig, &mf, &ext, &entry), -ENXIO);
	zassert_equal(mf.key_id, 7U);
	zassert_is_null(ext);
}

ZTEST(module_keys, test_revoked_key_refused)
{
	struct app_manifest mf;
	struct llext *ext;
	void *entry = NULL;

	zassert_equal(load(revoked_manifest, revoked_sig, &mf, &ext, &entry), -ECANCELED);
	zassert_equal(mf.key_id, 3U);
	zassert_is_null(ext);
	zassert_equal(load_file("revoked", revoked_manifest, revoked_sig, &mf, &ext, &entry),
		      -ECANCELED);
	zassert_is_null(ext);
}

/* A manifest naming a listed key it was not signed with. */
ZTEST(module_keys, test_signature_of_another_key_refused)
{
	struct app_manifest mf;
	struct llext *ext = NULL;
	void *entry = NULL;

	memcpy(module_work, mod_bytes, sizeof(mod_bytes));
	memcpy(&mf, b_manifest, sizeof(mf));
	mf.key_id = 1U;
	zassert_equal(app_loader_verify_load_manifest(&mf, sizeof(mf), b_sig, sizeof(b_sig),
						      module_work, sizeof(mod_bytes), "app_main",
						      &ext, &entry),
		      -EPERM);
	zassert_is_null(ext);
}

ZTEST(module_keys, test_name_outside_prefix_refused)
{
	struct app_manifest mf;
	struct llext *ext;
	void *entry = NULL;

	zassert_equal(load(bname_manifest, bname_sig, &mf, &ext, &entry), -EPERM);
	zassert_equal(mf.key_id, 2U);
	zassert_is_null(ext);
}

ZTEST(module_keys, test_key_ceiling_bounds_caps)
{
	struct app_manifest mf;
	struct llext *ext;
	void *entry = NULL;
	app_caps_t caps = 0U;
	int id;

	zassert_equal(load(b_manifest, b_sig, &mf, &ext, &entry), 0);
	zassert_equal(mf.requested_caps, REQUESTED);
	id = launch_stopped(mf.name, ext, entry, &caps);
	zassert_true(id >= 0, "launch failed (%d)", id);
	zassert_equal(caps, APP_CAP_LOG, "held %#llx", (unsigned long long)caps);
	remove_app(id);
}

ZTEST(module_keys, test_required_cap_outside_key_ceiling_refused)
{
	struct app_manifest mf;
	struct llext *ext;
	void *entry = NULL;
	app_caps_t caps = 0U;

	zassert_equal(load(breq_manifest, breq_sig, &mf, &ext, &entry), 0);
	zassert_equal(launch_stopped(mf.name, ext, entry, &caps), -EPERM);
	unload(ext);
}

ZTEST(module_keys, test_two_publishers_load)
{
	struct app_manifest mf_a;
	struct app_manifest mf_b;
	struct llext *ext_a;
	struct llext *ext_b;
	void *entry_a = NULL;
	void *entry_b = NULL;
	app_caps_t caps_a = 0U;
	app_caps_t caps_b = 0U;
	int id_a;
	int id_b;

	zassert_equal(load(a_caps_manifest, a_caps_sig, &mf_a, &ext_a, &entry_a), 0);
	zassert_equal(load_file("b_mod", b_manifest, b_sig, &mf_b, &ext_b, &entry_b), 0);
	id_a = launch_stopped(mf_a.name, ext_a, entry_a, &caps_a);
	zassert_true(id_a >= 0, "launch of key 1 failed (%d)", id_a);
	id_b = launch_stopped(mf_b.name, ext_b, entry_b, &caps_b);
	zassert_true(id_b >= 0, "launch of key 2 failed (%d)", id_b);
	zassert_equal(caps_a, REQUESTED, "key 1 held %#llx", (unsigned long long)caps_a);
	zassert_equal(caps_b, APP_CAP_LOG, "key 2 held %#llx", (unsigned long long)caps_b);
	remove_app(id_a);
	remove_app(id_b);
}

static int autostart_from_registry(const struct app_record *rec, void *user)
{
	union app_manifest_buf mf;
	uint8_t sig[APP_MANIFEST_SIG_LEN];
	size_t mf_len = 0;
	struct llext *ext = NULL;
	void *entry = NULL;
	char path[64];
	int rc;

	ARG_UNUSED(user);
	if (strcmp(rec->name, "testmod") != 0) {
		return -ENOENT;
	}
	rc = app_registry_load_manifest(rec->name, &mf, &mf_len, sig, sizeof(sig));
	if (rc == 0) {
		rc = app_registry_blob_path(rec->name, path, sizeof(path));
	}
	if (rc == 0) {
		rc = app_loader_verify_load_manifest_file(&mf.mf, mf_len, sig, sizeof(sig), path,
							  "app_main", &ext, &entry);
	}
	if (rc == 0) {
		rc = app_platform_launch_llext(mf.mf.name, ext, (app_entry_t)entry, NULL,
					       APP_CAP_ALL);
		if (rc < 0) {
			unload(ext);
		}
	}
	return rc;
}

ZTEST(module_keys, test_refused_key_recorded_at_autostart)
{
	const struct {
		const uint8_t *mf;
		const uint8_t *sig;
		int err;
	} cases[] = {
		{revoked_manifest, revoked_sig, -ECANCELED},
		{unknown_manifest, unknown_sig, -ENXIO},
	};
	int err;

	zassert_equal(app_registry_load(), 0);
	for (size_t i = 0; i < ARRAY_SIZE(cases); i++) {
		zassert_equal(app_registry_store_blob("testmod", mod_bytes, sizeof(mod_bytes)), 0);
		zassert_equal(app_registry_store_manifest("testmod",
							  (const struct app_manifest *)cases[i].mf,
							  sizeof(struct app_manifest), cases[i].sig,
							  APP_MANIFEST_SIG_LEN),
			      0);
		zassert_equal(app_registry_install("testmod", true), 0);
		err = 1;
		zassert_true(app_registry_autostart_all(autostart_from_registry, NULL) >= 0);
		zassert_equal(app_registry_autostart_result("testmod", &err), 0);
		zassert_equal(err, cases[i].err, "recorded %d", err);
		zassert_equal(app_registry_uninstall("testmod"), 0);
	}
}

ZTEST_SUITE(module_keys, NULL, NULL, NULL, NULL, NULL);
```

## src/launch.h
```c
/*
 * Copyright (c) 2026 Espressif Systems (Shanghai) Co., Ltd.
 *
 * SPDX-License-Identifier: Apache-2.0
 */

#ifndef APP_PLATFORM_TEST_LAUNCH_H_
#define APP_PLATFORM_TEST_LAUNCH_H_

#include <zephyr/app_platform/app_platform.h>
#include <zephyr/kernel.h>

#define SETTLE_MS 20

static inline void settle_then_run(void *entry)
{
	k_msleep(SETTLE_MS);
	((app_entry_t)entry)(NULL);
}

/* On SMP, delay an application's own code until the test has set up its domain. */
static inline int launch_app(const struct app_def *def)
{
	struct app_def d = *def;

	if (IS_ENABLED(CONFIG_SMP)) {
		d.arg = (void *)d.entry;
		d.entry = settle_then_run;
	}
	return app_platform_launch(&d);
}

#endif /* APP_PLATFORM_TEST_LAUNCH_H_ */
```

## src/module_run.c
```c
/*
 * Copyright (c) 2026 Espressif Systems (Shanghai) Co., Ltd.
 *
 * SPDX-License-Identifier: Apache-2.0
 */

#include <zephyr/ztest.h>
#include <zephyr/app_platform/app_platform.h>
#include <zephyr/kernel.h>
#include <errno.h>
#include <string.h>

#include "module_run.h"

uint8_t module_work[MODULE_WORK_SIZE] __aligned(8);

static char watched[32];
static atomic_t watched_faulted;

static void watch_reclaimed(int id)
{
	struct app_platform_status st;

	if (app_platform_status(id, &st) == 0 && st.faulted && st.name != NULL &&
	    strncmp(st.name, watched, sizeof(watched)) == 0) {
		atomic_set(&watched_faulted, 1);
	}
}

void module_watch(const char *name)
{
	static bool hooked;

	if (!hooked) {
		zassert_equal(app_platform_on_reclaim(watch_reclaimed), 0);
		hooked = true;
	}
	strncpy(watched, name, sizeof(watched) - 1U);
	atomic_clear(&watched_faulted);
}

bool module_faulted(void)
{
	return atomic_get(&watched_faulted) != 0;
}

static bool running(int id)
{
	struct app_platform_status st;

	return app_platform_status(id, &st) == 0 && st.name != NULL &&
	       strncmp(st.name, watched, sizeof(watched)) == 0;
}

int module_wait_end(int id, int ms)
{
	for (int i = 0; i < ms / 5 && running(id); i++) {
		k_msleep(5);
	}
	if (running(id)) {
		(void)app_platform_remove(id);
		for (int i = 0; i < 400 && running(id); i++) {
			k_msleep(5);
		}
		return -ETIMEDOUT;
	}
	return module_faulted() ? -EFAULT : 0;
}
```

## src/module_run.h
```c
/*
 * Copyright (c) 2026 Espressif Systems (Shanghai) Co., Ltd.
 *
 * SPDX-License-Identifier: Apache-2.0
 */

#ifndef APP_PLATFORM_TEST_MODULE_RUN_H_
#define APP_PLATFORM_TEST_MODULE_RUN_H_

#include <stdbool.h>
#include <stdint.h>

#define MODULE_WORK_SIZE (8192 + 256)

/* Mutable copy of a module, shared by the suites. */
extern uint8_t module_work[MODULE_WORK_SIZE];

/* Record whether the application named @p name faults from now on. */
void module_watch(const char *name);

/* Whether the watched application faulted since module_watch(). */
bool module_faulted(void);

/* Wait up to @p ms for the watched application to end. Returns 0 when it
 * returned, -EFAULT when it faulted, and -ETIMEDOUT when it was still running,
 * in which case it is removed.
 */
int module_wait_end(int id, int ms);

#endif /* APP_PLATFORM_TEST_MODULE_RUN_H_ */
```
